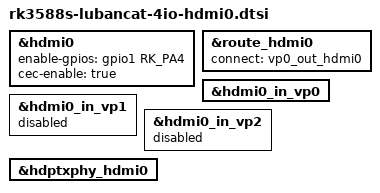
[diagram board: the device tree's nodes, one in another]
// SPDX-License-Identifier: (GPL-2.0+ OR MIT)
/*
 * Copyright (c) 2021 Rockchip Electronics Co., Ltd.
 * Copyright (c) 2023 EmbedFire <embedfire@embedfire.com>
 */

/dts-v1/;

/* hdmi0 display */
&hdmi0 {
	enable-gpios = <&gpio1 RK_PA4 GPIO_ACTIVE_HIGH>;
	cec-enable = "true";
	status = "okay";
};

&route_hdmi0{
	status = "okay";
	connect = <&vp0_out_hdmi0>;
};

&hdmi0_in_vp0 {
	status = "okay";
};

&hdmi0_in_vp1 {
	status = "disabled";
};

&hdmi0_in_vp2 {
	status = "disabled";
};

&hdptxphy_hdmi0 {
	status = "okay";
};
